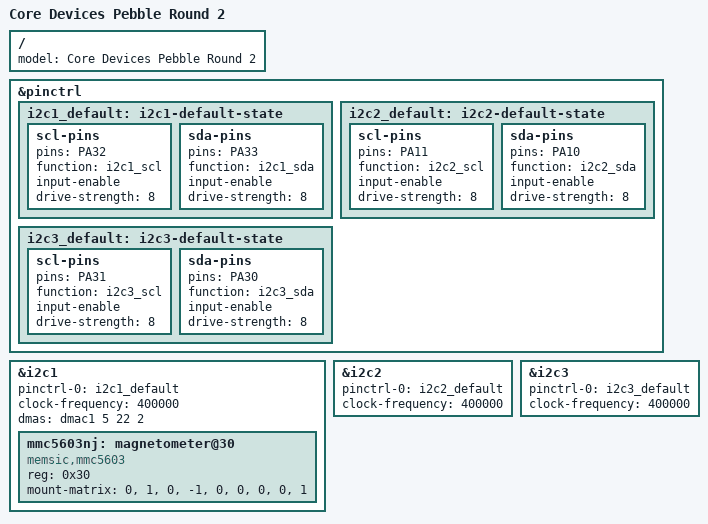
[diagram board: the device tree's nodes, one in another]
// SPDX-FileCopyrightText: 2026 Core Devices LLC
// SPDX-License-Identifier: (GPL-2.0-only OR BSD-2-Clause)

#include "sf32lb/sf32lb52x/sf32lb52.dtsi"

/ {
	model = "Core Devices Pebble Round 2";
};

&pinctrl {
	i2c1_default: i2c1-default-state {
		scl-pins {
			pins = "PA32";
			function = "i2c1_scl";
			input-enable;
			drive-strength = <8>;
		};

		sda-pins {
			pins = "PA33";
			function = "i2c1_sda";
			input-enable;
			drive-strength = <8>;
		};
	};

	i2c2_default: i2c2-default-state {
		scl-pins {
			pins = "PA11";
			function = "i2c2_scl";
			input-enable;
			drive-strength = <8>;
		};

		sda-pins {
			pins = "PA10";
			function = "i2c2_sda";
			input-enable;
			drive-strength = <8>;
		};
	};

	i2c3_default: i2c3-default-state {
		scl-pins {
			pins = "PA31";
			function = "i2c3_scl";
			input-enable;
			drive-strength = <8>;
		};

		sda-pins {
			pins = "PA30";
			function = "i2c3_sda";
			input-enable;
			drive-strength = <8>;
		};
	};
};

&i2c1 {
	pinctrl-0 = <&i2c1_default>;
	pinctrl-names = "default";
	clock-frequency = <400000>;
	dmas = <&dmac1 5 22 2>;
	dma-names = "rx";
	status = "okay";

	mmc5603nj: magnetometer@30 {
		compatible = "memsic,mmc5603";
		reg = <0x30>;
		mount-matrix = "0", "1", "0",
			       "-1", "0", "0",
			       "0", "0", "1";
	};
};

&i2c2 {
	pinctrl-0 = <&i2c2_default>;
	pinctrl-names = "default";
	clock-frequency = <400000>;
	status = "okay";
};

&i2c3 {
	pinctrl-0 = <&i2c3_default>;
	pinctrl-names = "default";
	clock-frequency = <400000>;
	status = "okay";
};
